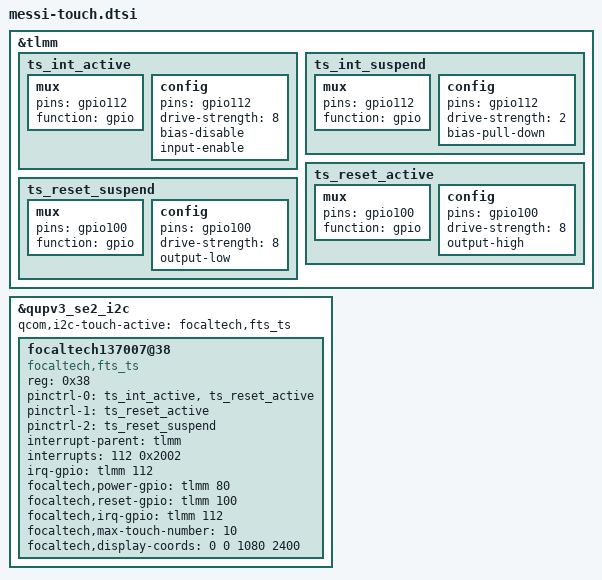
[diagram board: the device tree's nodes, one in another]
&tlmm {
	ts_int_active: ts_int_active {
		mux {
			pins = "gpio112";
			function = "gpio";
		};

		config {
			pins = "gpio112";
			drive-strength = <8>;
			bias-disable;
			input-enable;
		};
	};

	ts_int_suspend: ts_int_suspend {
		mux {
			pins = "gpio112";
			function = "gpio";
		};

		config {
			pins = "gpio112";
			drive-strength = <2>;
			bias-pull-down;
		};
	};

	ts_reset_active: ts_reset_active {
		mux {
			pins = "gpio100";
			function = "gpio";
		};

		config {
			pins = "gpio100";
			drive-strength = <8>;
			output-high;
		};
	};

	ts_reset_suspend: ts_reset_suspend {
		mux {
			pins = "gpio100";
			function = "gpio";
		};

		config {
			pins = "gpio100";
			drive-strength = <8>;
			output-low;
		};
	};
};
&qupv3_se2_i2c {
	#address-cells = <1>;
	#size-cells = <0>;
	status = "okay";
		/*pinctrl for rst and int*/
	qcom,i2c-touch-active="focaltech,fts_ts";

	focaltech137007@38 {
		status = "okay";
		compatible = "focaltech,fts_ts";
		reg = <0x38>;
		pinctrl-names = "default", "pin_set_high", "pin_set_low";
        	pinctrl-0 = <&ts_int_active &ts_reset_active>;
        	pinctrl-1 = <&ts_reset_active>;
       		pinctrl-2 = <&ts_reset_suspend>;
		interrupt-parent = <&tlmm>;
		interrupts = <112 0x2002>;
		//reset-gpio = <&tlmm 100 0x00>;
		//reset-pinctrl = <1>;
		irq-gpio = <&tlmm 112 0x2002>;
		focaltech,power-gpio = <&tlmm 80 0x00>;
		focaltech,reset-gpio = <&tlmm 100 0x00>;
		focaltech,irq-gpio = <&tlmm 112 0x2002>;
		focaltech,max-touch-number = <10>;
		//focaltech,ic-type = 0x35180481;
		focaltech,display-coords =  <0 0 1080 2400>;
		//vdd-supply = <&tlmm 80 0x00>;
	};
};
